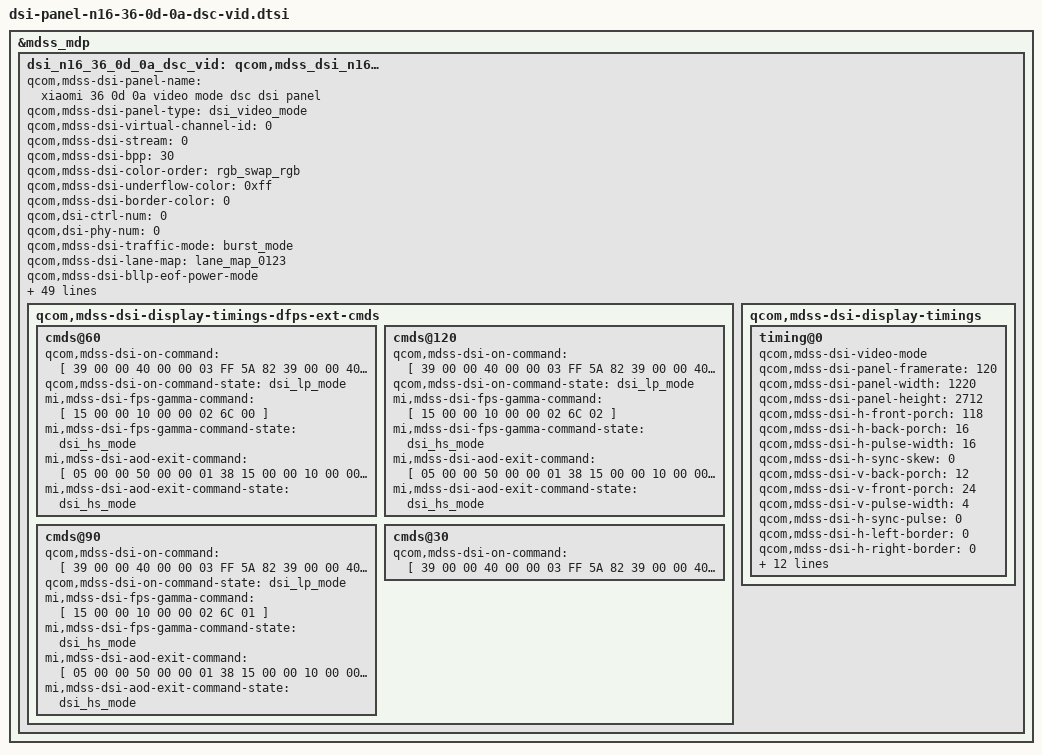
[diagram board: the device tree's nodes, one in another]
&mdss_mdp {
	dsi_n16_36_0d_0a_dsc_vid: qcom,mdss_dsi_n16_36_0d_0a_dsc_vid {
		qcom,mdss-dsi-panel-name = "xiaomi 36 0d 0a video mode dsc dsi panel";
		qcom,mdss-dsi-panel-type = "dsi_video_mode";
		qcom,mdss-dsi-virtual-channel-id = <0>;
		qcom,mdss-dsi-stream = <0>;
		qcom,mdss-dsi-bpp = <30>;
		qcom,mdss-dsi-color-order = "rgb_swap_rgb";
		qcom,mdss-dsi-underflow-color = <0xff>;
		qcom,mdss-dsi-border-color = <0>;

		qcom,dsi-ctrl-num = <0>;
		qcom,dsi-phy-num = <0>;

		qcom,mdss-dsi-traffic-mode = "burst_mode";
		qcom,mdss-dsi-lane-map = "lane_map_0123";
		qcom,mdss-dsi-bllp-eof-power-mode;
		qcom,mdss-dsi-bllp-power-mode;
		qcom,mdss-dsi-lane-0-state;
		qcom,mdss-dsi-lane-1-state;
		qcom,mdss-dsi-lane-2-state;
		qcom,mdss-dsi-lane-3-state;
		qcom,mdss-dsi-dma-trigger = "trigger_sw";
		qcom,mdss-dsi-mdp-trigger = "none";
		qcom,mdss-dsi-reset-sequence = <1 20>, <0 5>, <1 20>;
		qcom,mdss-pan-physical-width-dimension = <695>;
		qcom,mdss-pan-physical-height-dimension = <1545>;

		qcom,mdss-dsi-tx-eot-append;
		qcom,mdss-dsi-lp11-init;
		qcom,mdss-dsi-bl-inverted-dbv;
		qcom,bl-update-flag = "delay_until_first_frame";

		//qcom,mdss-dsi-panel-hdr-enabled;
		//qcom,mdss-dsi-panel-hdr-color-primaries = <14500 15500 32000 17000 15500 30000 8000 3000>;
		//qcom,mdss-dsi-panel-peak-brightness = <4200000>;
		//qcom,mdss-dsi-panel-blackness-level = <3230>;

		qcom,mdss-dsi-pan-enable-dynamic-fps;
		qcom,mdss-dsi-pan-fps-update =
			"dfps_immediate_porch_mode_vfp";
		qcom,dsi-supported-dfps-list = <60 120 90 30>;

		mi,mdss-dsi-panel-cell-id-read-command = [06 01 00 02 00 00 01 5A];
		mi,mdss-dsi-panel-cell-id-read-command-state = "dsi_hs_mode";
		mi,mdss-dsi-panel-cell-id-read-length = <14>;

		mi,mdss-dsi-panel-wp-read-command = [06 01 00 02 00 00 01 A1];
		mi,mdss-dsi-panel-wp-read-command-state = "dsi_hs_mode";
		mi,mdss-dsi-panel-wp-read-length = <3>;

		qcom,mdss-dsi-display-timings-dfps-ext-cmds {
			cmds@60{
				qcom,mdss-dsi-on-command = [
					/*Optimize Panel VGHR power on speed*/
					39 00 00 40 00 00 03 FF 5A 82
					39 00 00 40 00 00 02 F9 01
					39 00 00 40 00 00 02 65 05
					39 00 00 40 00 00 02 F9 81
					39 00 00 40 00 00 03 FF 5A 81
					39 00 00 40 00 00 02 65 02
					39 00 00 00 00 00 02 F4 27
					/*Video Trim Code*/
					39 00 00 40 00 00 03 F0 AA 12
					39 00 00 40 00 00 04 C3 E1 20 50
					39 00 00 40 00 00 02 65 11
					39 00 00 40 00 00 0F C3 00 63 00 63 00 63 00 63 00 63 00 63 00 63
					39 00 00 40 00 00 11 CC 2B 1D 2B 1D 2B 1D 2B 1D 2B 1D 2B 1D 2B 1D 04 BF
					/*RU Code*/
					39 00 00 40 00 00 03 F0 AA 18
					39 00 00 40 00 00 0F B0 13 96 00 1E 02 F4 06 D0 78 D7 E8 06 00 00
					39 00 00 40 00 00 0C B1 3F 00 00 00 00 00 00 00 00 00 00
					39 00 00 40 00 00 10 C0 50 3E 39 17 39 C4 71 C0 C3 72 AA 15 4C B5 68
					39 00 00 40 00 00 10 C1 47 A4 12 29 24 99 D1 28 95 3B 1D 8E E7 73 B8
					39 00 00 40 00 00 10 C2 3B 9E 0F 07 83 C1 E0 F0 58 2C 16 0E E7 72 B8
					39 00 00 40 00 00 10 C3 2B 95 CE C5 62 B1 54 AA 74 2A 15 0A 65 32 90
					39 00 00 40 00 00 10 C4 29 14 4A 25 02 81 3C 9E 4E 26 93 49 84 B2 58
					39 00 00 40 00 00 10 C5 25 12 89 24 81 41 1C 8C 45 22 91 08 62 32 10
					39 00 00 40 00 00 10 C6 20 90 04 05 F2 F1 74 B8 5C 2D 96 8B 25 81 C0
					39 00 00 40 00 00 10 C7 1B 8D 86 A5 42 98 CC 64 31 18 0B C5 C4 D2 60
					39 00 00 40 00 00 10 C8 25 92 89 24 81 40 9C 4C 25 12 10 C8 44 12 00
					39 00 00 40 00 00 10 C9 2F 97 8B A5 C2 D9 68 B2 58 1C 0D C6 C3 51 A0
					39 00 00 40 00 00 10 CA 19 8C 86 23 01 78 B8 5A 2C 15 8A 85 22 81 38
					39 00 00 40 00 00 10 CB 13 09 44 82 31 10 84 40 00 00 00 00 00 00 00
					39 00 00 40 00 00 10 E0 08 40 B4 9C A2 62 08 04 91 A7 0A 86 B2 30 8C
					39 00 00 40 00 00 10 E1 22 C4 90 19 A3 4B CA B0 15 70 22 5C 23 AE 03
					39 00 00 40 00 00 10 E2 43 20 33 29 A0 19 D4 D8 4E B8 11 4E A6 3A 12
					39 00 00 40 00 00 10 E3 00 88 63 A5 6C 74 22 11 0C A6 39 D0 A5 B1 AD
					39 00 00 40 00 00 10 E4 73 E1 19 4E 94 AD AF 7C 67 3A DE F9 DE FB DF
					39 00 00 40 00 00 10 E5 6B 59 8B 52 4F D5 A4 EB CB 96 86 65 A9 EE 9B
					39 00 00 40 00 00 10 E6 9E A5 98 5B B3 CF EB B8 5B 60 AE BF 3C 70 14
					39 00 00 40 00 00 10 E7 C7 01 3B EF D1 A6 37 E0 00 00 DF 40 00 00 00
					39 00 00 40 00 00 10 E8 A5 B1 AE 78 00 00 01 2A 56 D8 CE B7 CE FB F9
					39 00 00 00 00 00 10 E9 CE 40 00 7F A0 00 38 00 00 1F 00 00 00 00 00
					39 00 00 40 00 00 03 F0 AA 12
					39 00 00 40 00 00 02 65 01
					39 00 00 40 00 00 02 BE 01
					39 00 00 40 00 00 03 F0 AA 10
					39 00 00 40 00 00 02 D0 84
					39 00 00 40 00 00 03 F0 AA 12
					39 00 00 40 00 00 02 65 02
					39 00 00 40 00 00 02 D1 00
					/*Vfp Mask*/
					39 00 00 40 00 00 03 F0 AA 10
					39 00 00 40 00 00 04 B8 32 00 0A
					39 00 00 40 00 00 04 B9 01 18 00
					/*GIR ON/OFF Dimming*/
					39 00 00 40 00 00 03 F0 AA 11
					39 00 00 40 00 00 02 65 02
					39 00 00 40 00 00 03 D5 66 66
					/*Fix Abnormal Voltage in Elvss*/
					39 00 00 40 00 00 03 F0 AA 10
					39 00 00 40 00 00 02 65 02
					39 00 00 40 00 00 04 D0 90 14 C0
					/*Active High Error Low*/
					39 00 00 40 00 00 03 F0 AA 10
					39 00 00 40 00 00 02 65 01
					39 00 00 40 00 00 02 CF 87
					39 00 00 40 00 00 02 65 08
					39 00 00 00 00 00 02 CF 0F
					/*Compression Mode*/
					39 00 00 40 00 00 02 03 01
					39 00 00 40 00 00 02 35 00
					39 00 00 40 00 00 02 53 20
					39 00 00 40 00 00 02 59 09
					39 00 00 40 00 00 02 5D 00
					39 00 00 40 00 00 02 6F 01
					39 00 00 40 00 00 02 6C 00
					39 00 00 40 00 00 03 F0 AA 10
					39 00 00 40 00 00 08 B0 05 4C 01 31 01 04 C4
					39 00 00 40 00 00 03 FF 5A 80
					39 00 00 40 00 00 02 65 0A
					39 00 00 40 00 00 02 F9 A8
					39 00 00 40 00 00 03 FF 5A 81
					39 00 00 40 00 00 02 65 19
					39 00 00 40 00 00 02 F8 01
					39 00 00 40 00 00 02 65 03
					39 00 00 40 00 00 04 FB F3 F3 F3
					39 00 00 40 00 00 03 F0 AA 00
					39 00 00 40 00 00 03 FF 5A 00
					39 00 00 00 78 00 02 11 00
					/* Display On */
					39 00 00 00 0A 00 02 29 00
				];
				qcom,mdss-dsi-on-command-state = "dsi_lp_mode";
				mi,mdss-dsi-fps-gamma-command = [
					15 00 00 10 00 00 02 6C 00
				];
				mi,mdss-dsi-fps-gamma-command-state = "dsi_hs_mode";

				mi,mdss-dsi-aod-exit-command = [
					05 00 00 50 00 00 01 38
					15 00 00 10 00 00 02 6C 00
				];
				mi,mdss-dsi-aod-exit-command-state = "dsi_hs_mode";

				#include "dsi-panel-n16-36-0d-0a-dsc-vid-common.dtsi"
			};
			cmds@120{
				qcom,mdss-dsi-on-command = [
					/*Optimize Panel VGHR power on speed*/
					39 00 00 40 00 00 03 FF 5A 82
					39 00 00 40 00 00 02 F9 01
					39 00 00 40 00 00 02 65 05
					39 00 00 40 00 00 02 F9 81
					39 00 00 40 00 00 03 FF 5A 81
					39 00 00 40 00 00 02 65 02
					39 00 00 00 00 00 02 F4 27
					/*Video Trim Code*/
					39 00 00 40 00 00 03 F0 AA 12
					39 00 00 40 00 00 04 C3 E1 20 50
					39 00 00 40 00 00 02 65 11
					39 00 00 40 00 00 0F C3 00 63 00 63 00 63 00 63 00 63 00 63 00 63
					39 00 00 40 00 00 11 CC 2B 1D 2B 1D 2B 1D 2B 1D 2B 1D 2B 1D 2B 1D 04 BF
					/*RU Code*/
					39 00 00 40 00 00 03 F0 AA 18
					39 00 00 40 00 00 0F B0 13 96 00 1E 02 F4 06 D0 78 D7 E8 06 00 00
					39 00 00 40 00 00 0C B1 3F 00 00 00 00 00 00 00 00 00 00
					39 00 00 40 00 00 10 C0 50 3E 39 17 39 C4 71 C0 C3 72 AA 15 4C B5 68
					39 00 00 40 00 00 10 C1 47 A4 12 29 24 99 D1 28 95 3B 1D 8E E7 73 B8
					39 00 00 40 00 00 10 C2 3B 9E 0F 07 83 C1 E0 F0 58 2C 16 0E E7 72 B8
					39 00 00 40 00 00 10 C3 2B 95 CE C5 62 B1 54 AA 74 2A 15 0A 65 32 90
					39 00 00 40 00 00 10 C4 29 14 4A 25 02 81 3C 9E 4E 26 93 49 84 B2 58
					39 00 00 40 00 00 10 C5 25 12 89 24 81 41 1C 8C 45 22 91 08 62 32 10
					39 00 00 40 00 00 10 C6 20 90 04 05 F2 F1 74 B8 5C 2D 96 8B 25 81 C0
					39 00 00 40 00 00 10 C7 1B 8D 86 A5 42 98 CC 64 31 18 0B C5 C4 D2 60
					39 00 00 40 00 00 10 C8 25 92 89 24 81 40 9C 4C 25 12 10 C8 44 12 00
					39 00 00 40 00 00 10 C9 2F 97 8B A5 C2 D9 68 B2 58 1C 0D C6 C3 51 A0
					39 00 00 40 00 00 10 CA 19 8C 86 23 01 78 B8 5A 2C 15 8A 85 22 81 38
					39 00 00 40 00 00 10 CB 13 09 44 82 31 10 84 40 00 00 00 00 00 00 00
					39 00 00 40 00 00 10 E0 08 40 B4 9C A2 62 08 04 91 A7 0A 86 B2 30 8C
					39 00 00 40 00 00 10 E1 22 C4 90 19 A3 4B CA B0 15 70 22 5C 23 AE 03
					39 00 00 40 00 00 10 E2 43 20 33 29 A0 19 D4 D8 4E B8 11 4E A6 3A 12
					39 00 00 40 00 00 10 E3 00 88 63 A5 6C 74 22 11 0C A6 39 D0 A5 B1 AD
					39 00 00 40 00 00 10 E4 73 E1 19 4E 94 AD AF 7C 67 3A DE F9 DE FB DF
					39 00 00 40 00 00 10 E5 6B 59 8B 52 4F D5 A4 EB CB 96 86 65 A9 EE 9B
					39 00 00 40 00 00 10 E6 9E A5 98 5B B3 CF EB B8 5B 60 AE BF 3C 70 14
					39 00 00 40 00 00 10 E7 C7 01 3B EF D1 A6 37 E0 00 00 DF 40 00 00 00
					39 00 00 40 00 00 10 E8 A5 B1 AE 78 00 00 01 2A 56 D8 CE B7 CE FB F9
					39 00 00 00 00 00 10 E9 CE 40 00 7F A0 00 38 00 00 1F 00 00 00 00 00
					39 00 00 40 00 00 03 F0 AA 12
					39 00 00 40 00 00 02 65 01
					39 00 00 40 00 00 02 BE 01
					39 00 00 40 00 00 03 F0 AA 10
					39 00 00 40 00 00 02 D0 84
					39 00 00 40 00 00 03 F0 AA 12
					39 00 00 40 00 00 02 65 02
					39 00 00 40 00 00 02 D1 00
					/*Vfp Mask*/
					39 00 00 40 00 00 03 F0 AA 10
					39 00 00 40 00 00 04 B8 32 00 0A
					39 00 00 40 00 00 04 B9 01 18 00
					/*GIR ON/OFF Dimming*/
					39 00 00 40 00 00 03 F0 AA 11
					39 00 00 40 00 00 02 65 02
					39 00 00 40 00 00 03 D5 66 66
					/*Fix Abnormal Voltage in Elvss*/
					39 00 00 40 00 00 03 F0 AA 10
					39 00 00 40 00 00 02 65 02
					39 00 00 40 00 00 04 D0 90 14 C0
					/*Active High Error Low*/
					39 00 00 40 00 00 03 F0 AA 10
					39 00 00 40 00 00 02 65 01
					39 00 00 40 00 00 02 CF 87
					39 00 00 40 00 00 02 65 08
					39 00 00 00 00 00 02 CF 0F
					/*Compression Mode*/
					39 00 00 40 00 00 02 03 01
					39 00 00 40 00 00 02 35 00
					39 00 00 40 00 00 02 53 20
					39 00 00 40 00 00 02 59 09
					39 00 00 40 00 00 02 5D 00
					39 00 00 40 00 00 02 6F 01
					39 00 00 40 00 00 02 6C 02
					39 00 00 40 00 00 03 F0 AA 10
					39 00 00 40 00 00 08 B0 05 4C 01 31 01 04 C4
					39 00 00 40 00 00 03 FF 5A 80
					39 00 00 40 00 00 02 65 0A
					39 00 00 40 00 00 02 F9 A8
					39 00 00 40 00 00 03 FF 5A 81
					39 00 00 40 00 00 02 65 19
					39 00 00 40 00 00 02 F8 01
					39 00 00 40 00 00 02 65 03
					39 00 00 40 00 00 04 FB F3 F3 F3
					39 00 00 40 00 00 03 F0 AA 00
					39 00 00 40 00 00 03 FF 5A 00
					39 00 00 00 78 00 02 11 00
					/* Display On */
					39 00 00 00 0A 00 02 29 00
				];
				qcom,mdss-dsi-on-command-state = "dsi_lp_mode";
				mi,mdss-dsi-fps-gamma-command = [
					15 00 00 10 00 00 02 6C 02
				];
				mi,mdss-dsi-fps-gamma-command-state = "dsi_hs_mode";

				mi,mdss-dsi-aod-exit-command = [
					05 00 00 50 00 00 01 38
					15 00 00 10 00 00 02 6C 02
				];
				mi,mdss-dsi-aod-exit-command-state = "dsi_hs_mode";

				#include "dsi-panel-n16-36-0d-0a-dsc-vid-common.dtsi"
			};

			cmds@90{
				qcom,mdss-dsi-on-command = [
					/*Optimize Panel VGHR power on speed*/
					39 00 00 40 00 00 03 FF 5A 82
					39 00 00 40 00 00 02 F9 01
					39 00 00 40 00 00 02 65 05
					39 00 00 40 00 00 02 F9 81
					39 00 00 40 00 00 03 FF 5A 81
					39 00 00 40 00 00 02 65 02
					39 00 00 00 00 00 02 F4 27
					/*Video Trim Code*/
					39 00 00 40 00 00 03 F0 AA 12
					39 00 00 40 00 00 04 C3 E1 20 50
					39 00 00 40 00 00 02 65 11
					39 00 00 40 00 00 0F C3 00 63 00 63 00 63 00 63 00 63 00 63 00 63
					39 00 00 40 00 00 11 CC 2B 1D 2B 1D 2B 1D 2B 1D 2B 1D 2B 1D 2B 1D 04 BF
					/*RU Code*/
					39 00 00 40 00 00 03 F0 AA 18
					39 00 00 40 00 00 0F B0 13 96 00 1E 02 F4 06 D0 78 D7 E8 06 00 00
					39 00 00 40 00 00 0C B1 3F 00 00 00 00 00 00 00 00 00 00
					39 00 00 40 00 00 10 C0 50 3E 39 17 39 C4 71 C0 C3 72 AA 15 4C B5 68
					39 00 00 40 00 00 10 C1 47 A4 12 29 24 99 D1 28 95 3B 1D 8E E7 73 B8
					39 00 00 40 00 00 10 C2 3B 9E 0F 07 83 C1 E0 F0 58 2C 16 0E E7 72 B8
					39 00 00 40 00 00 10 C3 2B 95 CE C5 62 B1 54 AA 74 2A 15 0A 65 32 90
					39 00 00 40 00 00 10 C4 29 14 4A 25 02 81 3C 9E 4E 26 93 49 84 B2 58
					39 00 00 40 00 00 10 C5 25 12 89 24 81 41 1C 8C 45 22 91 08 62 32 10
					39 00 00 40 00 00 10 C6 20 90 04 05 F2 F1 74 B8 5C 2D 96 8B 25 81 C0
					39 00 00 40 00 00 10 C7 1B 8D 86 A5 42 98 CC 64 31 18 0B C5 C4 D2 60
					39 00 00 40 00 00 10 C8 25 92 89 24 81 40 9C 4C 25 12 10 C8 44 12 00
					39 00 00 40 00 00 10 C9 2F 97 8B A5 C2 D9 68 B2 58 1C 0D C6 C3 51 A0
					39 00 00 40 00 00 10 CA 19 8C 86 23 01 78 B8 5A 2C 15 8A 85 22 81 38
					39 00 00 40 00 00 10 CB 13 09 44 82 31 10 84 40 00 00 00 00 00 00 00
					39 00 00 40 00 00 10 E0 08 40 B4 9C A2 62 08 04 91 A7 0A 86 B2 30 8C
					39 00 00 40 00 00 10 E1 22 C4 90 19 A3 4B CA B0 15 70 22 5C 23 AE 03
					39 00 00 40 00 00 10 E2 43 20 33 29 A0 19 D4 D8 4E B8 11 4E A6 3A 12
					39 00 00 40 00 00 10 E3 00 88 63 A5 6C 74 22 11 0C A6 39 D0 A5 B1 AD
					39 00 00 40 00 00 10 E4 73 E1 19 4E 94 AD AF 7C 67 3A DE F9 DE FB DF
					39 00 00 40 00 00 10 E5 6B 59 8B 52 4F D5 A4 EB CB 96 86 65 A9 EE 9B
					39 00 00 40 00 00 10 E6 9E A5 98 5B B3 CF EB B8 5B 60 AE BF 3C 70 14
					39 00 00 40 00 00 10 E7 C7 01 3B EF D1 A6 37 E0 00 00 DF 40 00 00 00
					39 00 00 40 00 00 10 E8 A5 B1 AE 78 00 00 01 2A 56 D8 CE B7 CE FB F9
					39 00 00 00 00 00 10 E9 CE 40 00 7F A0 00 38 00 00 1F 00 00 00 00 00
					39 00 00 40 00 00 03 F0 AA 12
					39 00 00 40 00 00 02 65 01
					39 00 00 40 00 00 02 BE 01
					39 00 00 40 00 00 03 F0 AA 10
					39 00 00 40 00 00 02 D0 84
					39 00 00 40 00 00 03 F0 AA 12
					39 00 00 40 00 00 02 65 02
					39 00 00 40 00 00 02 D1 00
					/*Vfp Mask*/
					39 00 00 40 00 00 03 F0 AA 10
					39 00 00 40 00 00 04 B8 32 00 0A
					39 00 00 40 00 00 04 B9 01 18 00
					/*GIR ON/OFF Dimming*/
					39 00 00 40 00 00 03 F0 AA 11
					39 00 00 40 00 00 02 65 02
					39 00 00 40 00 00 03 D5 66 66
					/*Fix Abnormal Voltage in Elvss*/
					39 00 00 40 00 00 03 F0 AA 10
					39 00 00 40 00 00 02 65 02
					39 00 00 40 00 00 04 D0 90 14 C0
					/*Active High Error Low*/
					39 00 00 40 00 00 03 F0 AA 10
					39 00 00 40 00 00 02 65 01
					39 00 00 40 00 00 02 CF 87
					39 00 00 40 00 00 02 65 08
					39 00 00 00 00 00 02 CF 0F
					/*Compression Mode*/
					39 00 00 40 00 00 02 03 01
					39 00 00 40 00 00 02 35 00
					39 00 00 40 00 00 02 53 20
					39 00 00 40 00 00 02 59 09
					39 00 00 40 00 00 02 5D 00
					39 00 00 40 00 00 02 6F 01
					39 00 00 40 00 00 02 6C 01
					39 00 00 40 00 00 03 F0 AA 10
					39 00 00 40 00 00 08 B0 05 4C 01 31 01 04 C4
					39 00 00 40 00 00 03 FF 5A 80
					39 00 00 40 00 00 02 65 0A
					39 00 00 40 00 00 02 F9 A8
					39 00 00 40 00 00 03 FF 5A 81
					39 00 00 40 00 00 02 65 19
					39 00 00 40 00 00 02 F8 01
					39 00 00 40 00 00 02 65 03
					39 00 00 40 00 00 04 FB F3 F3 F3
					39 00 00 40 00 00 03 F0 AA 00
					39 00 00 40 00 00 03 FF 5A 00
					39 00 00 00 78 00 02 11 00
					/* Display On */
					39 00 00 00 0A 00 02 29 00
				];
				qcom,mdss-dsi-on-command-state = "dsi_lp_mode";
				mi,mdss-dsi-fps-gamma-command = [
					15 00 00 10 00 00 02 6C 01
				];
				mi,mdss-dsi-fps-gamma-command-state = "dsi_hs_mode";

				mi,mdss-dsi-aod-exit-command = [
					05 00 00 50 00 00 01 38
					15 00 00 10 00 00 02 6C 01
				];
				mi,mdss-dsi-aod-exit-command-state = "dsi_hs_mode";

				#include "dsi-panel-n16-36-0d-0a-dsc-vid-common.dtsi"
			};

			cmds@30{
				qcom,mdss-dsi-on-command = [
					/*Optimize Panel VGHR power on speed*/
					39 00 00 40 00 00 03 FF 5A 82
					39 00 00 40 00 00 02 F9 01
					39 00 00 40 00 00 02 65 05
					39 00 00 40 00 00 02 F9 81
					39 00 00 40 00 00 03 FF 5A 81
					39 00 00 40 00 00 02 65 02
					39 00 00 00 00 00 02 F4 27
					/*Video Trim Code*/
					39 00 00 40 00 00 03 F0 AA 12
					39 00 00 40 00 00 04 C3 E1 20 50
					39 00 00 40 00 00 02 65 11
					39 00 00 40 00 00 0F C3 00 63 00 63 00 63 00 63 00 63 00 63 00 63
					39 00 00 40 00 00 11 CC 2B 1D 2B 1D 2B 1D 2B 1D 2B 1D 2B 1D 2B 1D 04 BF
					/*RU Code*/
					39 00 00 40 00 00 03 F0 AA 18
					39 00 00 40 00 00 0F B0 13 96 00 1E 02 F4 06 D0 78 D7 E8 06 00 00
					39 00 00 40 00 00 0C B1 3F 00 00 00 00 00 00 00 00 00 00
					39 00 00 40 00 00 10 C0 50 3E 39 17 39 C4 71 C0 C3 72 AA 15 4C B5 68
					39 00 00 40 00 00 10 C1 47 A4 12 29 24 99 D1 28 95 3B 1D 8E E7 73 B8
					39 00 00 40 00 00 10 C2 3B 9E 0F 07 83 C1 E0 F0 58 2C 16 0E E7 72 B8
					39 00 00 40 00 00 10 C3 2B 95 CE C5 62 B1 54 AA 74 2A 15 0A 65 32 90
					39 00 00 40 00 00 10 C4 29 14 4A 25 02 81 3C 9E 4E 26 93 49 84 B2 58
					39 00 00 40 00 00 10 C5 25 12 89 24 81 41 1C 8C 45 22 91 08 62 32 10
					39 00 00 40 00 00 10 C6 20 90 04 05 F2 F1 74 B8 5C 2D 96 8B 25 81 C0
					39 00 00 40 00 00 10 C7 1B 8D 86 A5 42 98 CC 64 31 18 0B C5 C4 D2 60
					39 00 00 40 00 00 10 C8 25 92 89 24 81 40 9C 4C 25 12 10 C8 44 12 00
					39 00 00 40 00 00 10 C9 2F 97 8B A5 C2 D9 68 B2 58 1C 0D C6 C3 51 A0
					39 00 00 40 00 00 10 CA 19 8C 86 23 01 78 B8 5A 2C 15 8A 85 22 81 38
					39 00 00 40 00 00 10 CB 13 09 44 82 31 10 84 40 00 00 00 00 00 00 00
					39 00 00 40 00 00 10 E0 08 40 B4 9C A2 62 08 04 91 A7 0A 86 B2 30 8C
					39 00 00 40 00 00 10 E1 22 C4 90 19 A3 4B CA B0 15 70 22 5C 23 AE 03
					39 00 00 40 00 00 10 E2 43 20 33 29 A0 19 D4 D8 4E B8 11 4E A6 3A 12
					39 00 00 40 00 00 10 E3 00 88 63 A5 6C 74 22 11 0C A6 39 D0 A5 B1 AD
					39 00 00 40 00 00 10 E4 73 E1 19 4E 94 AD AF 7C 67 3A DE F9 DE FB DF
					39 00 00 40 00 00 10 E5 6B 59 8B 52 4F D5 A4 EB CB 96 86 65 A9 EE 9B
					39 00 00 40 00 00 10 E6 9E A5 98 5B B3 CF EB B8 5B 60 AE BF 3C 70 14
					39 00 00 40 00 00 10 E7 C7 01 3B EF D1 A6 37 E0 00 00 DF 40 00 00 00
					39 00 00 40 00 00 10 E8 A5 B1 AE 78 00 00 01 2A 56 D8 CE B7 CE FB F9
					39 00 00 00 00 00 10 E9 CE 40 00 7F A0 00 38 00 00 1F 00 00 00 00 00
					39 00 00 40 00 00 03 F0 AA 12
					39 00 00 40 00 00 02 65 01
					39 00 00 40 00 00 02 BE 01
					39 00 00 40 00 00 03 F0 AA 10
					39 00 00 40 00 00 02 D0 84
					39 00 00 40 00 00 03 F0 AA 12
					39 00 00 40 00 00 02 65 02
					39 00 00 40 00 00 02 D1 00
					/*Vfp Mask*/
					39 00 00 40 00 00 03 F0 AA 10
					39 00 00 40 00 00 04 B8 32 00 0A
					39 00 00 40 00 00 04 B9 01 18 00
					/*GIR ON/OFF Dimming*/
					39 00 00 40 00 00 03 F0 AA 11
					39 00 00 40 00 00 02 65 02
					39 00 00 40 00 00 03 D5 66 66
					/*Fix Abnormal Voltage in Elvss*/
					39 00 00 40 00 00 03 F0 AA 10
					39 00 00 40 00 00 02 65 02
					39 00 00 40 00 00 04 D0 90 14 C0
					/*Active High Error Low*/
					39 00 00 40 00 00 03 F0 AA 10
					39 00 00 40 00 00 02 65 01
					39 00 00 40 00 00 02 CF 87
					39 00 00 40 00 00 02 65 08
					39 00 00 00 00 00 02 CF 0F
					/*Compression Mode*/
					39 00 00 40 00 00 02 03 01
					39 00 00 40 00 00 02 35 00
					39 00 00 40 00 00 02 53 20
					39 00 00 40 00 00 02 59 09
					39 00 00 40 00 00 02 5D 00
					39 00 00 40 00 00 02 6F 01
					39 00 00 40 00 00 02 6C 02
					39 00 00 40 00 00 03 F0 AA 10
					39 00 00 40 00 00 08 B0 05 4C 01 31 01 04 C4
					39 00 00 40 00 00 03 FF 5A 80
					39 00 00 40 00 00 02 65 0A
					39 00 00 40 00 00 02 F9 A8
					39 00 00 40 00 00 03 FF 5A 81
					39 00 00 40 00 00 02 65 19
					39 00 00 40 00 00 02 F8 01
					39 00 00 40 00 00 02 65 03
					39 00 00 40 00 00 04 FB F3 F3 F3
					39 00 00 40 00 00 03 F0 AA 00
					39 00 00 40 00 00 03 FF 5A 00
					39 00 00 00 78 00 02 11 00
					/* Display On */
					39 00 00 00 0A 00 02 29 00
				];

				#include "dsi-panel-n16-36-0d-0a-dsc-vid-common.dtsi"
			};
		};

		qcom,mdss-dsi-display-timings {
			timing@0{
				qcom,mdss-dsi-video-mode;
				qcom,mdss-dsi-panel-framerate = <120>;
				qcom,mdss-dsi-panel-width = <1220>;
				qcom,mdss-dsi-panel-height = <2712>;
				qcom,mdss-dsi-h-front-porch = <118>;
				qcom,mdss-dsi-h-back-porch = <16>;
				qcom,mdss-dsi-h-pulse-width = <16>;
				qcom,mdss-dsi-h-sync-skew = <0>;
				qcom,mdss-dsi-v-back-porch = <12>;
				qcom,mdss-dsi-v-front-porch = <24>;
				qcom,mdss-dsi-v-pulse-width = <4>;
				qcom,mdss-dsi-h-sync-pulse = <0>;
				qcom,mdss-dsi-h-left-border = <0>;
				qcom,mdss-dsi-h-right-border = <0>;
				qcom,mdss-dsi-v-top-border = <0>;
				qcom,mdss-dsi-v-bottom-border = <0>;
				qcom,compression-mode = "dsc";
				qcom,mdss-dsc-config-by-manufacture-cmd;
				qcom,mdss-dsc-version = <0x12>;
				qcom,mdss-dsc-scr-version = <0x0>;
				qcom,mdss-dsc-slice-height = <12>;
				qcom,mdss-dsc-slice-width = <610>;
				qcom,mdss-dsc-slice-per-pkt = <2>;
				qcom,mdss-dsc-bit-per-component = <10>;
				qcom,mdss-dsc-bit-per-pixel = <8>;
				qcom,mdss-dsc-block-prediction-enable;
			};
		};
	};
};

&dsi_n16_36_0d_0a_dsc_vid {
	mi,panel-id = <0x004e3136 0x00360d00>;

	mi,max-brightness-clone = <16383>;
	mi,normal-max-brightness-clone = <8191>;
	mi,mdss-dsi-fac-bl-max-level = <2047>;
	mi,mdss-fac-brightness-max-level = <2047>;
	mi,hbm-bl-min-level = <1>;
	mi,hbm-bl-max-level = <2047>;

	/* IRQF_ONESHOT | IRQF_TRIGGER_LOW */
	mi,esd-err-irq-gpio = <&tlmm 65 0x2008>;
	mi,panel-ignore-esd-in-aod;

	mi,thermal-dimming-flag;
	mi,panel-on-dimming-delay = <120>;
	mi,dimming-need-update-speed;
	mi,dimming-node = <0 200 450 800 4095>;

	mi,doze-hbm-dbv-level = <252>;
	mi,doze-lbm-dbv-level = <20>;
	mi,ddic-round-corner-enabled;

	//use fps cmdsets
	mi,video-fps-cmdsets-flag;
	mi,local-hbm-enabled;
	mi,local-hbm-ctrl-63-c5-reg;
	mi,need-fod-animal-in-normal-enabled;
	mi,local-hbm-ui-ready-delay-num-frame = <1>; /* 1 frame */
};
